# ESP32-C6 register map
Vendor: ESPRESSIF SYSTEMS (SHANGHAI) CO., LTD.; Series: ESP32 C-Series; File version: 2
CPU: RV32IMC r0p0, little endian, no MPU, no FPU, 4 interrupt priority bits
Address unit: 32 bits
Registers are 32-bit, read-write, reset 0x0 unless marked. A register's access mark holds for its fields unless they carry their own. Offsets are from the block's base; [hi:lo] are bit positions; {n}, {i} and the like mark numbered series.

## RMT — Remote Control Peripheral
Base 0x60006000
{0x0+4i} TX_CH{i}DATA (i=0..3) ro — The read and write data register for CHANNEL{i} by apb fifo access.
  [31:0] CHDATA — Read and write data for channel %s via APB FIFO.
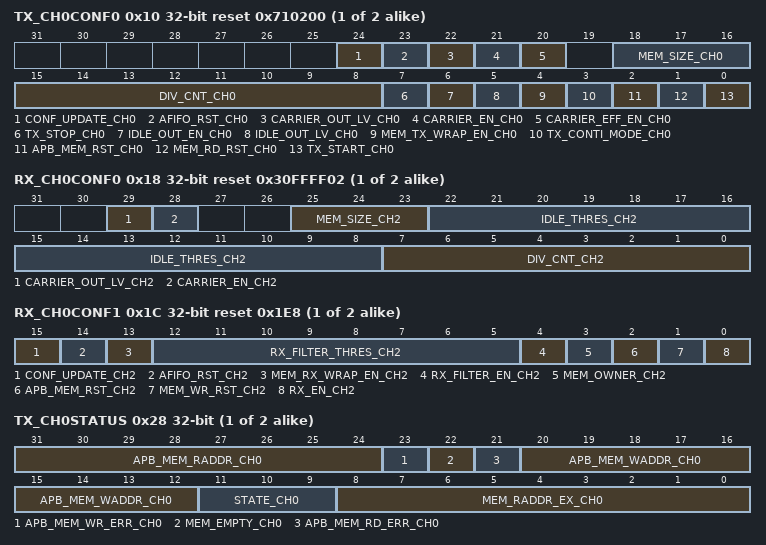
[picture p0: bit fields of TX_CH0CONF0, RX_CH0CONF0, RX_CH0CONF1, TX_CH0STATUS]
{0x10+4i} TX_CH{i}CONF0 (i=0..1) access per field reset 0x710200 — Channel {i} configure register 0
  [24] CONF_UPDATE_CH0 wo — synchronization bit for CHANNEL%s
  [23] AFIFO_RST_CH0 wo — Reserved
  [22] CARRIER_OUT_LV_CH0 rw — This bit is used to configure the position of carrier wave for CHANNEL%s. 1'h0: add carrier wave on low level. 1'h1: add carrier wave on high level.
  [21] CARRIER_EN_CH0 rw — This is the carrier modulation enable-control bit for CHANNEL%s. 1: Add carrier modulation in the output signal. 0: No carrier modulation in sig_out.
  [20] CARRIER_EFF_EN_CH0 rw — 1: Add carrier modulation on the output signal only at the send data state for CHANNEL%s. 0: Add carrier modulation on the output signal at all state for CHANNEL%s. Only valid when RMT_CARRIER_EN_CH%s is 1.
  [18:16] MEM_SIZE_CH0 rw — This register is used to configure the maximum size of memory allocated to CHANNEL%s.
  [15:8] DIV_CNT_CH0 rw — This register is used to configure the divider for clock of CHANNEL%s.
  [7] TX_STOP_CH0 rw — Set this bit to stop the transmitter of CHANNEL%s sending data out.
  [6] IDLE_OUT_EN_CH0 rw — This is the output enable-control bit for CHANNEL%s in IDLE state.
  [5] IDLE_OUT_LV_CH0 rw — This bit configures the level of output signal in CHANNEL%s when the latter is in IDLE state.
  [4] MEM_TX_WRAP_EN_CH0 rw — This is the channel %s enable bit for wraparound mode: it will resume sending at the start when the data to be sent is more than its memory size.
  [3] TX_CONTI_MODE_CH0 rw — Set this bit to restart transmission from the first data to the last data in CHANNEL%s.
  [2] APB_MEM_RST_CH0 wo — Set this bit to reset W/R ram address for CHANNEL%s by accessing apb fifo.
  [1] MEM_RD_RST_CH0 wo — Set this bit to reset read ram address for CHANNEL%s by accessing transmitter.
  [0] TX_START_CH0 wo — Set this bit to start sending data on CHANNEL%s.
{0x18+8i} RX_CH{i}CONF0 (i=0..1) reset 0x30FFFF02 — Channel {i} configure register 0
  [29] CARRIER_OUT_LV_CH2 — This bit is used to configure the position of carrier wave for CHANNEL%s. 1'h0: add carrier wave on low level. 1'h1: add carrier wave on high level.
  [28] CARRIER_EN_CH2 — This is the carrier modulation enable-control bit for CHANNEL%s. 1: Add carrier modulation in the output signal. 0: No carrier modulation in sig_out.
  [25:23] MEM_SIZE_CH2 — This register is used to configure the maximum size of memory allocated to CHANNEL%s.
  [22:8] IDLE_THRES_CH2 — When no edge is detected on the input signal and continuous clock cycles is longer than this register value, received process is finished.
  [7:0] DIV_CNT_CH2 — This register is used to configure the divider for clock of CHANNEL%s.
{0x1C+8i} RX_CH{i}CONF1 (i=0..1) access per field reset 0x1E8 — Channel {i} configure register 1
  [15] CONF_UPDATE_CH2 wo — synchronization bit for CHANNEL%s
  [14] AFIFO_RST_CH2 wo — Reserved
  [13] MEM_RX_WRAP_EN_CH2 rw — This is the channel %s enable bit for wraparound mode: it will resume receiving at the start when the data to be received is more than its memory size.
  [12:5] RX_FILTER_THRES_CH2 rw — Ignores the input pulse when its width is smaller than this register value in APB clock periods (in receive mode).
  [4] RX_FILTER_EN_CH2 rw — This is the receive filter's enable bit for CHANNEL%s.
  [3] MEM_OWNER_CH2 rw — This register marks the ownership of CHANNEL%s's ram block. 1'h1: Receiver is using the ram. 1'h0: APB bus is using the ram.
  [2] APB_MEM_RST_CH2 wo — Set this bit to reset W/R ram address for CHANNEL%s by accessing apb fifo.
  [1] MEM_WR_RST_CH2 wo — Set this bit to reset write ram address for CHANNEL%s by accessing receiver.
  [0] RX_EN_CH2 rw — Set this bit to enable receiver to receive data on CHANNEL%s.
{0x28+4i} TX_CH{i}STATUS (i=0..1) ro — Channel {i} status register
  [31:24] APB_MEM_RADDR_CH0 — This register records the memory address offset when reading RAM over APB bus.
  [23] APB_MEM_WR_ERR_CH0 — This status bit will be set if the offset address out of memory size when writes via APB bus.
  [22] MEM_EMPTY_CH0 — This status bit will be set when the data to be set is more than memory size and the wraparound mode is disabled.
  [21] APB_MEM_RD_ERR_CH0 — This status bit will be set if the offset address out of memory size when reading via APB bus.
  [20:12] APB_MEM_WADDR_CH0 — This register records the memory address offset when writes RAM over APB bus.
  [11:9] STATE_CH0 — This register records the FSM status of CHANNEL%s.
  [8:0] MEM_RADDR_EX_CH0 — This register records the memory address offset when transmitter of CHANNEL%s is using the RAM.
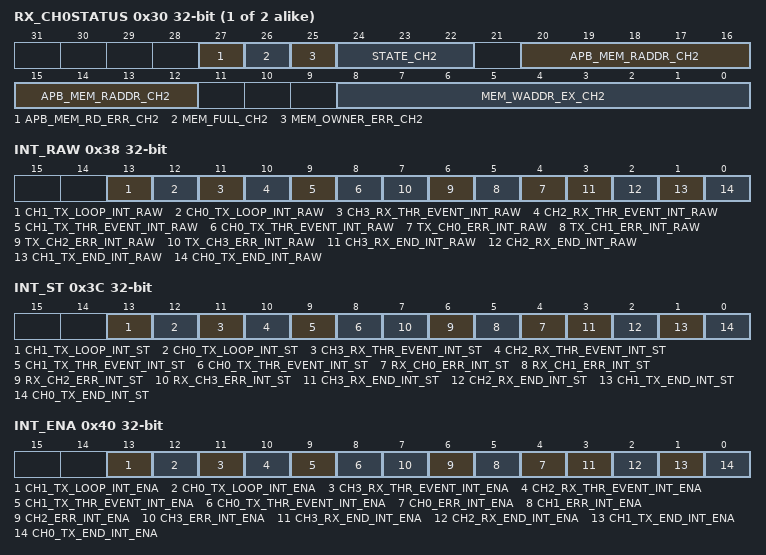
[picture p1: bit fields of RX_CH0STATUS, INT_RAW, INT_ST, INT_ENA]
{0x30+4i} RX_CH{i}STATUS (i=0..1) ro — Channel {i} status register
  [27] APB_MEM_RD_ERR_CH2 — This status bit will be set if the offset address out of memory size when reads via APB bus.
  [26] MEM_FULL_CH2 — This status bit will be set if the receiver receives more data than the memory size.
  [25] MEM_OWNER_ERR_CH2 — This status bit will be set when the ownership of memory block is wrong.
  [24:22] STATE_CH2 — This register records the FSM status of CHANNEL%s.
  [20:12] APB_MEM_RADDR_CH2 — This register records the memory address offset when reads RAM over APB bus.
  [8:0] MEM_WADDR_EX_CH2 — This register records the memory address offset when receiver of CHANNEL%s is using the RAM.
0x38 INT_RAW ro — Raw interrupt status
  [13] CH1_TX_LOOP_INT_RAW — The interrupt raw bit for CHANNEL1. Triggered when the loop count reaches the configured threshold value.
  [12] CH0_TX_LOOP_INT_RAW — The interrupt raw bit for CHANNEL0. Triggered when the loop count reaches the configured threshold value.
  [11] CH3_RX_THR_EVENT_INT_RAW — The interrupt raw bit for CHANNEL3. Triggered when receiver receive more data than configured value.
  [10] CH2_RX_THR_EVENT_INT_RAW — The interrupt raw bit for CHANNEL2. Triggered when receiver receive more data than configured value.
  [9] CH1_TX_THR_EVENT_INT_RAW — The interrupt raw bit for CHANNEL1. Triggered when transmitter sent more data than configured value.
  [8] CH0_TX_THR_EVENT_INT_RAW — The interrupt raw bit for CHANNEL0. Triggered when transmitter sent more data than configured value.
  [n+4] TX_CH{n}_ERR_INT_RAW (n=0..3) — The interrupt raw bit for CHANNEL{n+4}. Triggered when error occurs.
  [3] CH3_RX_END_INT_RAW — The interrupt raw bit for CHANNEL3. Triggered when reception done.
  [2] CH2_RX_END_INT_RAW — The interrupt raw bit for CHANNEL2. Triggered when reception done.
  [1] CH1_TX_END_INT_RAW — The interrupt raw bit for CHANNEL1. Triggered when transmission done.
  [0] CH0_TX_END_INT_RAW — The interrupt raw bit for CHANNEL0. Triggered when transmission done.
0x3C INT_ST ro — Masked interrupt status
  [13] CH1_TX_LOOP_INT_ST — The masked interrupt status bit for CH1_TX_LOOP_INT.
  [12] CH0_TX_LOOP_INT_ST — The masked interrupt status bit for CH0_TX_LOOP_INT.
  [11] CH3_RX_THR_EVENT_INT_ST — The masked interrupt status bit for CH3_RX_THR_EVENT_INT.
  [10] CH2_RX_THR_EVENT_INT_ST — The masked interrupt status bit for CH2_RX_THR_EVENT_INT.
  [9] CH1_TX_THR_EVENT_INT_ST — The masked interrupt status bit for CH1_TX_THR_EVENT_INT.
  [8] CH0_TX_THR_EVENT_INT_ST — The masked interrupt status bit for CH0_TX_THR_EVENT_INT.
  [n+4] RX_CH{n}_ERR_INT_ST (n=0..3) — The masked interrupt status bit for CH{n+4}_ERR_INT.
  [3] CH3_RX_END_INT_ST — The masked interrupt status bit for CH3_RX_END_INT.
  [2] CH2_RX_END_INT_ST — The masked interrupt status bit for CH2_RX_END_INT.
  [1] CH1_TX_END_INT_ST — The masked interrupt status bit for CH1_TX_END_INT.
  [0] CH0_TX_END_INT_ST — The masked interrupt status bit for CH0_TX_END_INT.
0x40 INT_ENA — Interrupt enable bits
  [13] CH1_TX_LOOP_INT_ENA — The interrupt enable bit for CH1_TX_LOOP_INT.
  [12] CH0_TX_LOOP_INT_ENA — The interrupt enable bit for CH0_TX_LOOP_INT.
  [11] CH3_RX_THR_EVENT_INT_ENA — The interrupt enable bit for CH3_RX_THR_EVENT_INT.
  [10] CH2_RX_THR_EVENT_INT_ENA — The interrupt enable bit for CH2_RX_THR_EVENT_INT.
  [9] CH1_TX_THR_EVENT_INT_ENA — The interrupt enable bit for CH1_TX_THR_EVENT_INT.
  [8] CH0_TX_THR_EVENT_INT_ENA — The interrupt enable bit for CH0_TX_THR_EVENT_INT.
  [n+4] CH{n}_ERR_INT_ENA (n=0..3) — The interrupt enable bit for CH{n+4}_ERR_INT.
  [3] CH3_RX_END_INT_ENA — The interrupt enable bit for CH3_RX_END_INT.
  [2] CH2_RX_END_INT_ENA — The interrupt enable bit for CH2_RX_END_INT.
  [1] CH1_TX_END_INT_ENA — The interrupt enable bit for CH1_TX_END_INT.
  [0] CH0_TX_END_INT_ENA — The interrupt enable bit for CH0_TX_END_INT.
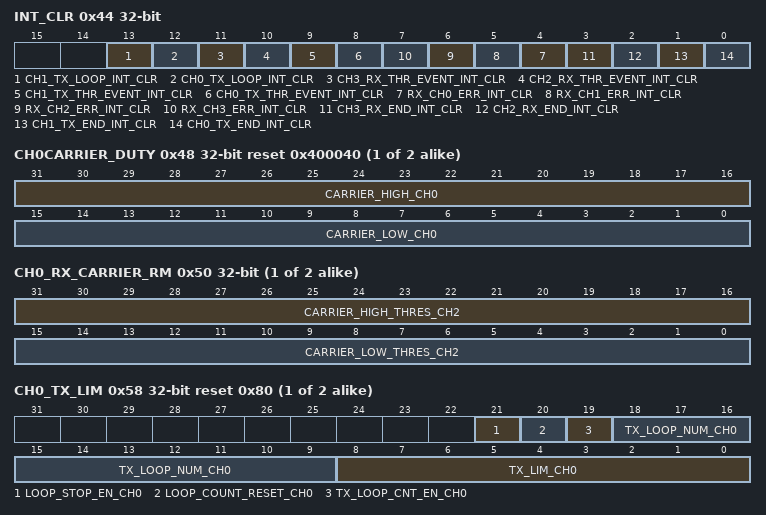
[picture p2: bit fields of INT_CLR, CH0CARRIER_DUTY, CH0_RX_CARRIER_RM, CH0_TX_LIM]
0x44 INT_CLR wo — Interrupt clear bits
  [13] CH1_TX_LOOP_INT_CLR — Set this bit to clear theCH1_TX_LOOP_INT interrupt.
  [12] CH0_TX_LOOP_INT_CLR — Set this bit to clear theCH0_TX_LOOP_INT interrupt.
  [11] CH3_RX_THR_EVENT_INT_CLR — Set this bit to clear theCH3_RX_THR_EVENT_INT interrupt.
  [10] CH2_RX_THR_EVENT_INT_CLR — Set this bit to clear theCH2_RX_THR_EVENT_INT interrupt.
  [9] CH1_TX_THR_EVENT_INT_CLR — Set this bit to clear theCH1_TX_THR_EVENT_INT interrupt.
  [8] CH0_TX_THR_EVENT_INT_CLR — Set this bit to clear theCH0_TX_THR_EVENT_INT interrupt.
  [n+4] RX_CH{n}_ERR_INT_CLR (n=0..3) — Set this bit to clear theCH{n+4}_ERR_INT interrupt.
  [3] CH3_RX_END_INT_CLR — Set this bit to clear theCH3_RX_END_INT interrupt.
  [2] CH2_RX_END_INT_CLR — Set this bit to clear theCH2_RX_END_INT interrupt.
  [1] CH1_TX_END_INT_CLR — Set this bit to clear theCH1_TX_END_INT interrupt.
  [0] CH0_TX_END_INT_CLR — Set this bit to clear theCH0_TX_END_INT interrupt.
{0x48+4i} CH{i}CARRIER_DUTY (i=0..1) reset 0x400040 — Channel {i} duty cycle configuration register
  [31:16] CARRIER_HIGH_CH0 — This register is used to configure carrier wave 's high level clock period for CHANNEL%s.
  [15:0] CARRIER_LOW_CH0 — This register is used to configure carrier wave 's low level clock period for CHANNEL%s.
{0x50+4i} CH{i}_RX_CARRIER_RM (i=0..1) — Channel {i} carrier remove register
  [31:16] CARRIER_HIGH_THRES_CH2 — The high level period in a carrier modulation mode is (REG_RMT_REG_CARRIER_HIGH_THRES_CH%s + 1) for channel %s.
  [15:0] CARRIER_LOW_THRES_CH2 — The low level period in a carrier modulation mode is (REG_RMT_REG_CARRIER_LOW_THRES_CH%s + 1) for channel %s.
{0x58+4i} CH{i}_TX_LIM (i=0..1) access per field reset 0x80 — Channel {i} Tx event configuration register
  [21] LOOP_STOP_EN_CH0 rw — This bit is used to enable the loop send stop function after the loop counter counts to loop number for CHANNEL%s.
  [20] LOOP_COUNT_RESET_CH0 wo — This register is used to reset the loop count when tx_conti_mode is valid.
  [19] TX_LOOP_CNT_EN_CH0 rw — This register is the enabled bit for loop count.
  [18:9] TX_LOOP_NUM_CH0 rw — This register is used to configure the maximum loop count when tx_conti_mode is valid.
  [8:0] TX_LIM_CH0 rw — This register is used to configure the maximum entries that CHANNEL%s can send out.
{0x60+4i} CH{i}_RX_LIM (i=0..1) reset 0x80 — Channel {i} Rx event configuration register
  [8:0] RMT_RX_LIM_CH2 — This register is used to configure the maximum entries that CHANNEL%s can receive.
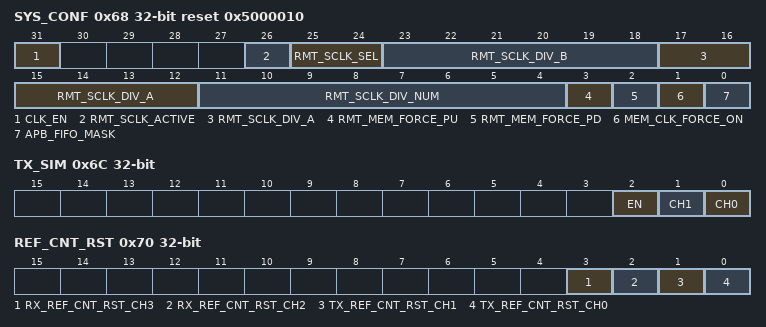
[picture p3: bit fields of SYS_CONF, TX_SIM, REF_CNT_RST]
0x68 SYS_CONF reset 0x5000010 — RMT apb configuration register
  [31] CLK_EN — RMT register clock gate enable signal. 1: Power up the drive clock of registers. 0: Power down the drive clock of registers
  [26] RMT_SCLK_ACTIVE — rmt_sclk switch
  [25:24] RMT_SCLK_SEL — choose the clock source of rmt_sclk. 1:CLK_80Mhz,2:CLK_FOSC, 3:XTAL
  [23:18] RMT_SCLK_DIV_B — the denominator of the fractional part of the fractional divisor
  [17:12] RMT_SCLK_DIV_A — the numerator of the fractional part of the fractional divisor
  [11:4] RMT_SCLK_DIV_NUM — the integral part of the fractional divisor
  [3] RMT_MEM_FORCE_PU — 1: Disable RMT memory light sleep power down function. 0: Power down RMT memory when RMT is in light sleep mode.
  [2] RMT_MEM_FORCE_PD — Set this bit to power down RMT memory.
  [1] MEM_CLK_FORCE_ON — Set this bit to enable the clock for RMT memory.
  [0] APB_FIFO_MASK — 1'h1: access memory directly. 1'h0: access memory by FIFO.
0x6C TX_SIM — RMT TX synchronous register
  [2] EN — This register is used to enable multiple of channels to start sending data synchronously.
  [1] CH1 — Set this bit to enable CHANNEL1 to start sending data synchronously with other enabled channels.
  [0] CH0 — Set this bit to enable CHANNEL0 to start sending data synchronously with other enabled channels.
0x70 REF_CNT_RST wo — RMT clock divider reset register
  [3] RX_REF_CNT_RST_CH3 — This register is used to reset the clock divider of CHANNEL3.
  [2] RX_REF_CNT_RST_CH2 — This register is used to reset the clock divider of CHANNEL2.
  [1] TX_REF_CNT_RST_CH1 — This register is used to reset the clock divider of CHANNEL1.
  [0] TX_REF_CNT_RST_CH0 — This register is used to reset the clock divider of CHANNEL0.
0xCC DATE reset 0x2108213 — RMT version register
  [27:0] RMT_DATE — This is the version register.
